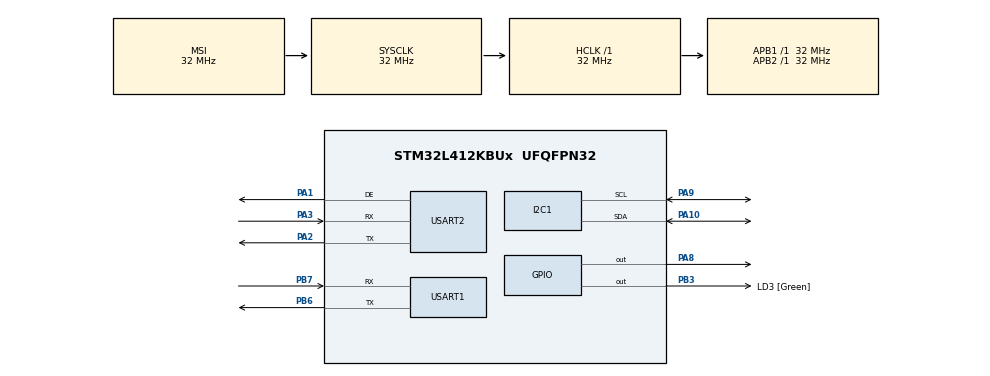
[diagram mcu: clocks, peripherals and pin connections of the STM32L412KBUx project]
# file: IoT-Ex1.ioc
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I2C1.Timing=0x00707CBB
Mcu.Family=STM32L4
Mcu.Name=STM32L412KBUx
Mcu.Package=UFQFPN32
NVIC.PriorityGroup=NVIC_PRIORITYGROUP_4
NVIC.USART2_IRQn=true\:0\:0\:false\:false\:true\:true\:true\:true
PA0-CK_IN.Mode=HSE-External-Clock-Source-for-LittleOrca
PA0-CK_IN.Signal=RCC_CK_IN
PA1.Mode=Hardware Flow Control (RS485)
PA1.Signal=USART2_DE
PA10.Mode=I2C
PA10.Signal=I2C1_SDA
PA13\ (JTMS/SWDIO).GPIO_Label=SWDIO
PA13\ (JTMS/SWDIO).Mode=Serial_Wire
PA13\ (JTMS/SWDIO).Signal=SYS_JTMS-SWDIO
PA14\ (JTCK/SWCLK).GPIO_Label=SWCLK
PA14\ (JTCK/SWCLK).Mode=Serial_Wire
PA14\ (JTCK/SWCLK).Signal=SYS_JTCK-SWCLK
PA2.Mode=Asynchronous
PA2.Signal=USART2_TX
PA3.Mode=Asynchronous
PA3.Signal=USART2_RX
PA8.Signal=GPIO_Output
PA9.Mode=I2C
PA9.Signal=I2C1_SCL
PB3\ (JTDO/TRACESWO).GPIO_Label=LD3 [Green]
PB3\ (JTDO/TRACESWO).Signal=GPIO_Output
PB6.Mode=Asynchronous
PB6.Signal=USART1_TX
PB7.Mode=Asynchronous
PB7.Signal=USART1_RX
PC14-OSC32_IN\ (PC14).Mode=LSE-External-Oscillator
PC14-OSC32_IN\ (PC14).Signal=RCC_OSC32_IN
PC15-OSC32_OUT\ (PC15).Mode=LSE-External-Oscillator
PC15-OSC32_OUT\ (PC15).Signal=RCC_OSC32_OUT
ProjectManager.HeapSize=0x200
ProjectManager.StackSize=0x400
ProjectManager.TargetToolchain=STM32CubeIDE
RCC.ADCFreq_Value=32000000
RCC.AHBFreq_Value=32000000
RCC.APB1Freq_Value=32000000
RCC.APB1TimFreq_Value=32000000
RCC.APB2Freq_Value=32000000
RCC.APB2TimFreq_Value=32000000
RCC.CortexFreq_Value=32000000
RCC.FLatency=FLASH_LATENCY_1
RCC.HCLKFreq_Value=32000000
RCC.HSE_VALUE=8000000
RCC.HSI48_VALUE=48000000
RCC.HSICalibrationValue=16
RCC.HSI_VALUE=16000000
RCC.LSE_Drive_Capability=RCC_LSEDRIVE_LOW
RCC.MSIClockRange=RCC_MSIRANGE_10
RCC.MSI_VALUE=32000000
RCC.SYSCLKFreq_VALUE=32000000
RCC.USBFreq_Value=32000000
RCC.VCOOutputFreq_Value=256000000
USART1.VirtualMode-Asynchronous=VM_ASYNC
USART2.VirtualMode-Asynchronous=VM_ASYNC
USART2.VirtualMode-Hardware\ Flow\ Control\ (RS485)=VM_ASYNC
board=NUCLEO-L412KB

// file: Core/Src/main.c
/* USER CODE BEGIN Header */
/**
  ******************************************************************************
  * @file           : main.c
  * @brief          : Main program body
  ******************************************************************************
  * @attention
  *
  * Copyright (c) 2023 STMicroelectronics.
  * All rights reserved.
  *
  * This software is licensed under terms that can be found in the LICENSE file
  * in the root directory of this software component.
  * If no LICENSE file comes with this software, it is provided AS-IS.
  *
  ******************************************************************************
  */
/* USER CODE END Header */
#include "main.h"

/* USER CODE BEGIN Includes */
#include "dash7.h"
#include "SHT40.h"
#include "LTR329.h"
/* USER CODE END Includes */

/* USER CODE BEGIN PTD */
uint8_t Rx_data[3];
uint8_t BT_data[8];

I2C_HandleTypeDef hi2c1;

UART_HandleTypeDef huart1;
UART_HandleTypeDef huart2;

float radiation;
// Add a global flag to indicate whether data is ready
volatile uint8_t dataReadyFlag = 0;
uint8_t ledStatus = 0; // 0 means LED is off, 1 means LED is on
/* USER CODE END PTD */

I2C_HandleTypeDef hi2c1;
UART_HandleTypeDef huart2;

void SystemClock_Config(void);
static void MX_GPIO_Init(void);
static void MX_USART2_UART_Init(void);
static void MX_USART1_UART_Init(void);
static void MX_I2C1_Init(void);

/* USER CODE BEGIN 0 */
void SHT40_Init()
{
	HAL_I2C_Init(&hi2c1); // Initialize and configure the I2C peripheral
}
void SHT40_Read(float *t, float *rh, uint8_t mode)
{
	uint8_t data[2] = {mode, 0x00};
	uint8_t buffer[6];

    HAL_I2C_Master_Transmit(&hi2c1, SHT40_I2C_ADDRESS, data, 2, HAL_MAX_DELAY);
    HAL_Delay(10);
    HAL_I2C_Master_Receive(&hi2c1, SHT40_I2C_ADDRESS, buffer, 6, HAL_MAX_DELAY);

    uint16_t t_ticks = buffer[0]*256 + buffer[1];
    uint16_t rh_ticks = buffer[3]*256 + buffer[4];

    float t_degC = -45 + 175.0 * t_ticks/65535;
    float rh_pRH = -6 + 125.0 * rh_ticks/65535;

    if (rh_pRH > 100){
    	rh_pRH = 100; }
    if (rh_pRH < 0){
    	rh_pRH = 0; }

    *t = t_degC;
    *rh = rh_pRH;
}

void LTR329_Init() {
    uint8_t data;

    // Activate the sensor
    data = LTR329_ACTIVE_MODE;
    HAL_I2C_Mem_Write(&hi2c1, LTR329_I2C_ADDRESS, LTR329_ALS_CONTR, I2C_MEMADD_SIZE_8BIT, &data, 1, 100);

    // Set measurement rate
    data = LTR329_MEAS_RATE;
    HAL_I2C_Mem_Write(&hi2c1, LTR329_I2C_ADDRESS, LTR329_ALS_MEAS_RATE, I2C_MEMADD_SIZE_8BIT, &data, 1, 100);
}

void LTR329_Read_Light(uint16_t *ch0, uint16_t *ch1) {
    uint8_t data[4];

    // Read 4 bytes of data starting from LTR329_ALS_DATA_CH1_0
    HAL_I2C_Mem_Read(&hi2c1, LTR329_I2C_ADDRESS, LTR329_ALS_DATA_CH1_0, I2C_MEMADD_SIZE_8BIT, data, 4, 100);

    // Combine bytes to get the light data for each channel
    *ch1 = (uint16_t)(data[1] << 8) | data[0];
    *ch0 = (uint16_t)(data[3] << 8) | data[2];
}

void HAL_UART_RxCpltCallback(UART_HandleTypeDef *huart){
	if (huart->Instance == USART2) {
		dataReadyFlag = 1;
		//ledStatus = 1 - ledStatus;
		//HAL_GPIO_WritePin(GPIOB, LD3_Pin, ledStatus);
	} else {
		return;
	}
}

/* USER CODE END 0 */

int main(void)
{
  /* USER CODE BEGIN 1 */
	float t, rh;
	uint16_t light_ch0, light_ch1;

  /* USER CODE END 1 */

  /* MCU Configuration--------------------------------------------------------*/

  /* Reset of all peripherals, Initializes the Flash interface and the Systick. */
  HAL_Init();

  /* Configure the system clock */
  SystemClock_Config();

  /* USER CODE BEGIN SysInit */
  __enable_irq();
  HAL_UART_IRQHandler(&huart1);
  HAL_UART_IRQHandler(&huart2);
  /* USER CODE END SysInit */

  /* Initialize all configured peripherals */
  MX_GPIO_Init();
  MX_USART2_UART_Init();
  MX_USART1_UART_Init();
  MX_I2C1_Init();
  /* USER CODE BEGIN 2 */
    SHT40_Init();
    LTR329_Init();
    uart_rx_buffer_clear();
    HAL_UART_Receive_IT(&huart2, Rx_data, 3);
    HAL_UART_Receive_IT(&huart1, BT_data, 8);

    static uint8_t txdata[] = {0x14, 0x87, 0x33} ;

    //HAL_GPIO_WritePin(GPIOB, LD3_Pin, 1);
  /* USER CODE END 2 */

  /* Infinite loop */
  /* USER CODE BEGIN WHILE */
  int counter = 0;
  while (1)
  {
	 /* LTR329_Read(data);
	  SHT40_Read(&t, &rh, SHT40_MEAS_HIGH_PRECISION);
	  float radiation = t*rh;
	  float dust = rh/t;*/
	  // Enter low-power mode if no data is ready

	  if (dataReadyFlag == 0){
		  printf("Entering low-power mode...\n");
		  // Enable UART interrupt and enter low-power mode
		  HAL_UART_Receive_IT(&huart2, Rx_data, 3);
	      //HAL_PWR_EnterSLEEPMode(PWR_LOWPOWERREGULATOR_ON, PWR_SLEEPENTRY_WFI);
	  }
	  else{
		  if (Rx_data[1] == 0x1) {
	  		  HAL_UART_Transmit(&huart1, txdata, 3, 10);

			  	  printf("Waking up from low-power mode...\n");
		  		  // Perform measurements
			  	  LTR329_Read_Light(&light_ch0, &light_ch1);
		  		  SHT40_Read(&t, &rh, SHT40_MEAS_HIGH_PRECISION);
		  		  float radiation = t*rh;
		  		  float light0 = (float)light_ch0;
		  		  float light1 = (float)light_ch1;

		  		  float dust = light0+t;

		  		  //HAL_GPIO_TogglePin(GPIOB, LD3_Pin);
		  		  // SEND TEMP
		  		  if(counter == 0){
		  			SHT40_Read(&t, &rh, SHT40_MEAS_HIGH_PRECISION);
			  		  uint8_t* TempBytes = create_payload_f(RESPONSE_TEMPERATURE, t);
			  		  HAL_UART_Transmit(&huart2, TempBytes, 7, 10);
			  		  free(TempBytes);
		  		  }else if(counter == 1){
			  		  uint8_t* HumBytes = create_payload_f(RESPONSE_HUMIDITY, rh);
			  		  HAL_UART_Transmit(&huart2, HumBytes, 7, 10);
			  		  free(HumBytes);
		  		  }else if(counter == 2){
			  		  uint8_t* LightBytes = create_payload_f(RESPONSE_LIGHT, light1);
			  		  HAL_UART_Transmit(&huart2, LightBytes, 7, 10);
			  		  free(LightBytes);
		  		  }else if(counter == 3){
			  		  uint8_t* RadBytes = create_payload_f(RESPONSE_RADIATION, radiation);
			  		  HAL_UART_Transmit(&huart2, RadBytes, 7, 10);
			  		  free(RadBytes);

		  		  }else if(counter == 4){
			  		  HAL_GPIO_WritePin(GPIOA,GPIO_PIN_8,1);
			  		  uint8_t* DustBytes = create_payload_f(NEW_DUST, dust);
			  		  HAL_Delay(5000);
			  		  HAL_UART_Transmit(&huart1, DustBytes, 7, 10);
			  		  HAL_GPIO_WritePin(GPIOA,GPIO_PIN_8,0);
					  free(DustBytes);
					  counter = 0;
		  		  }
		  		  HAL_GPIO_WritePin(GPIOA,GPIO_PIN_11,1);
		  		  HAL_Delay(100);
		  		  HAL_GPIO_WritePin(GPIOA,GPIO_PIN_11,0);

		  		  counter++;
		  		  //Clear Rx Buffer
		  		  for (uint8_t i=0; i<3; i++) {
		  			  Rx_data[i] = 0;
		  		  }
		  		  // Data is processed, reset the flag
		  		  dataReadyFlag = 0;
		  	  }
	  }
	  //enum msg_type_e msg_type = Rx_data[1];

    /* USER CODE END WHILE */

    /* USER CODE BEGIN 3 */
	  HAL_Delay(100);
  }
  /* USER CODE END 3 */
}

void SystemClock_Config(void)
{
  RCC_OscInitTypeDef RCC_OscInitStruct = {0};
  RCC_ClkInitTypeDef RCC_ClkInitStruct = {0};

  /** Configure the main internal regulator output voltage
  */
  if (HAL_PWREx_ControlVoltageScaling(PWR_REGULATOR_VOLTAGE_SCALE1) != HAL_OK)
  {
    Error_Handler();
  }

  /** Configure LSE Drive Capability
  */
  HAL_PWR_EnableBkUpAccess();
  __HAL_RCC_LSEDRIVE_CONFIG(RCC_LSEDRIVE_LOW);

  /** Initializes the RCC Oscillators according to the specified parameters
  * in the RCC_OscInitTypeDef structure.
  */
  RCC_OscInitStruct.OscillatorType = RCC_OSCILLATORTYPE_LSE|RCC_OSCILLATORTYPE_MSI;
  RCC_OscInitStruct.LSEState = RCC_LSE_ON;
  RCC_OscInitStruct.MSIState = RCC_MSI_ON;
  RCC_OscInitStruct.MSICalibrationValue = 0;
  RCC_OscInitStruct.MSIClockRange = RCC_MSIRANGE_10;
  RCC_OscInitStruct.PLL.PLLState = RCC_PLL_NONE;
  if (HAL_RCC_OscConfig(&RCC_OscInitStruct) != HAL_OK)
  {
    Error_Handler();
  }

  /** Initializes the CPU, AHB and APB buses clocks
  */
  RCC_ClkInitStruct.ClockType = RCC_CLOCKTYPE_HCLK|RCC_CLOCKTYPE_SYSCLK
                              |RCC_CLOCKTYPE_PCLK1|RCC_CLOCKTYPE_PCLK2;
  RCC_ClkInitStruct.SYSCLKSource = RCC_SYSCLKSOURCE_MSI;
  RCC_ClkInitStruct.AHBCLKDivider = RCC_SYSCLK_DIV1;
  RCC_ClkInitStruct.APB1CLKDivider = RCC_HCLK_DIV1;
  RCC_ClkInitStruct.APB2CLKDivider = RCC_HCLK_DIV1;

  if (HAL_RCC_ClockConfig(&RCC_ClkInitStruct, FLASH_LATENCY_1) != HAL_OK)
  {
    Error_Handler();
  }

  /** Enable MSI Auto calibration
  */
  HAL_RCCEx_EnableMSIPLLMode();
}

static void MX_I2C1_Init(void)
{

  hi2c1.Instance = I2C1;
  hi2c1.Init.Timing = 0x00707CBB;
  hi2c1.Init.OwnAddress1 = 0;
  hi2c1.Init.AddressingMode = I2C_ADDRESSINGMODE_7BIT;
  hi2c1.Init.DualAddressMode = I2C_DUALADDRESS_DISABLE;
  hi2c1.Init.OwnAddress2 = 0;
  hi2c1.Init.OwnAddress2Masks = I2C_OA2_NOMASK;
  hi2c1.Init.GeneralCallMode = I2C_GENERALCALL_DISABLE;
  hi2c1.Init.NoStretchMode = I2C_NOSTRETCH_DISABLE;
  if (HAL_I2C_Init(&hi2c1) != HAL_OK)
  {
    Error_Handler();
  }

  /** Configure Analogue filter
  */
  if (HAL_I2CEx_ConfigAnalogFilter(&hi2c1, I2C_ANALOGFILTER_ENABLE) != HAL_OK)
  {
    Error_Handler();
  }

  /** Configure Digital filter
  */
  if (HAL_I2CEx_ConfigDigitalFilter(&hi2c1, 0) != HAL_OK)
  {
    Error_Handler();
  }

}

static void MX_USART2_UART_Init(void)
{

  huart2.Instance = USART2;
  huart2.Init.BaudRate = 115200;
  huart2.Init.WordLength = UART_WORDLENGTH_8B;
  huart2.Init.StopBits = UART_STOPBITS_1;
  huart2.Init.Parity = UART_PARITY_NONE;
  huart2.Init.Mode = UART_MODE_TX_RX;
  huart2.Init.HwFlowCtl = UART_HWCONTROL_NONE;
  huart2.Init.OverSampling = UART_OVERSAMPLING_16;
  huart2.Init.OneBitSampling = UART_ONE_BIT_SAMPLE_DISABLE;
  huart2.AdvancedInit.AdvFeatureInit = UART_ADVFEATURE_NO_INIT;
  if (HAL_RS485Ex_Init(&huart2, UART_DE_POLARITY_HIGH, 0, 0) != HAL_OK)
  {
    Error_Handler();
  }

}

static void MX_USART1_UART_Init(void)
{

  /* USER CODE BEGIN USART_Init 1 */

  /* USER CODE END USART2_Init 1 */
  huart1.Instance = USART2;
  huart1.Init.BaudRate = 115200;
  huart1.Init.WordLength = UART_WORDLENGTH_8B;
  huart1.Init.StopBits = UART_STOPBITS_1;
  huart1.Init.Parity = UART_PARITY_NONE;
  huart1.Init.Mode = UART_MODE_TX_RX;
  huart1.Init.HwFlowCtl = UART_HWCONTROL_NONE;
  huart1.Init.OverSampling = UART_OVERSAMPLING_16;
  huart1.Init.OneBitSampling = UART_ONE_BIT_SAMPLE_DISABLE;
  huart1.AdvancedInit.AdvFeatureInit = UART_ADVFEATURE_NO_INIT;
  if (HAL_RS485Ex_Init(&huart1, UART_DE_POLARITY_HIGH, 0, 0) != HAL_OK)
  {
    Error_Handler();
  }

}

static void MX_GPIO_Init(void)
{
  GPIO_InitTypeDef GPIO_InitStruct = {0};

  /* GPIO Ports Clock Enable */
  __HAL_RCC_GPIOC_CLK_ENABLE();
  __HAL_RCC_GPIOA_CLK_ENABLE();
  __HAL_RCC_GPIOB_CLK_ENABLE();

  /*Configure GPIO pin Output Level */
  HAL_GPIO_WritePin(LD3_GPIO_Port, LD3_Pin, GPIO_PIN_RESET);

  GPIO_InitStruct.Pin = GPIO_PIN_8;
  GPIO_InitStruct.Mode = GPIO_MODE_OUTPUT_PP;
  GPIO_InitStruct.Pull = GPIO_NOPULL;
  GPIO_InitStruct.Speed = GPIO_SPEED_FREQ_LOW;
  HAL_GPIO_Init(GPIOA, &GPIO_InitStruct);

  GPIO_InitStruct.Pin = GPIO_PIN_11;
  GPIO_InitStruct.Mode = GPIO_MODE_OUTPUT_PP;
  GPIO_InitStruct.Pull = GPIO_NOPULL;
  GPIO_InitStruct.Speed = GPIO_SPEED_FREQ_LOW;
  HAL_GPIO_Init(GPIOA, &GPIO_InitStruct);

  /*Configure GPIO pin : LD3_Pin */
  GPIO_InitStruct.Pin = LD3_Pin;
  GPIO_InitStruct.Mode = GPIO_MODE_OUTPUT_PP;
  GPIO_InitStruct.Pull = GPIO_NOPULL;
  GPIO_InitStruct.Speed = GPIO_SPEED_FREQ_LOW;
  HAL_GPIO_Init(LD3_GPIO_Port, &GPIO_InitStruct);

  /*Configure GPIO pins : PB6 PB7 */
  GPIO_InitStruct.Pin = GPIO_PIN_6|GPIO_PIN_7;
  GPIO_InitStruct.Mode = GPIO_MODE_AF_PP;
  GPIO_InitStruct.Pull = GPIO_NOPULL;
  GPIO_InitStruct.Speed = GPIO_SPEED_FREQ_VERY_HIGH;
  GPIO_InitStruct.Alternate = GPIO_AF7_USART1;
  HAL_GPIO_Init(GPIOB, &GPIO_InitStruct);

/* USER CODE BEGIN MX_GPIO_Init_2 */
  HAL_GPIO_WritePin(GPIOB, LD3_Pin, 0);
/* USER CODE END MX_GPIO_Init_2 */
}

void Error_Handler(void)
{
  __disable_irq();
  while (1)
  {
  }
}
